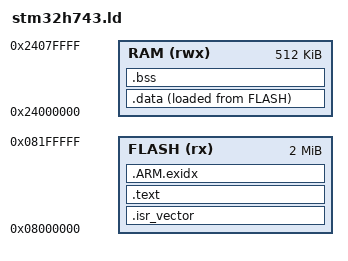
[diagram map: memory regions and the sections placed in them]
/* stm32h743.ld: flash @0x08000000 (2048K), RAM @0x24000000 (512K) */
ENTRY(Reset_Handler)
MEMORY
{
    FLASH (rx)  : ORIGIN = 0x08000000, LENGTH = 2048K
    RAM   (rwx) : ORIGIN = 0x24000000, LENGTH = 512K
}
_estack = ORIGIN(RAM) + LENGTH(RAM);
SECTIONS
{
    .isr_vector : { KEEP(*(.isr_vector)) } > FLASH
    .text : { *(.text*) *(.rodata*) . = ALIGN(4); } > FLASH
    .ARM.exidx : { *(.ARM.exidx*) } > FLASH
    _sidata = LOADADDR(.data);
    .data : { _sdata = .; *(.data*) . = ALIGN(4); _edata = .; } > RAM AT > FLASH
    .bss (NOLOAD) : { _sbss = .; *(.bss*) *(COMMON) . = ALIGN(4); _ebss = .; } > RAM
}
